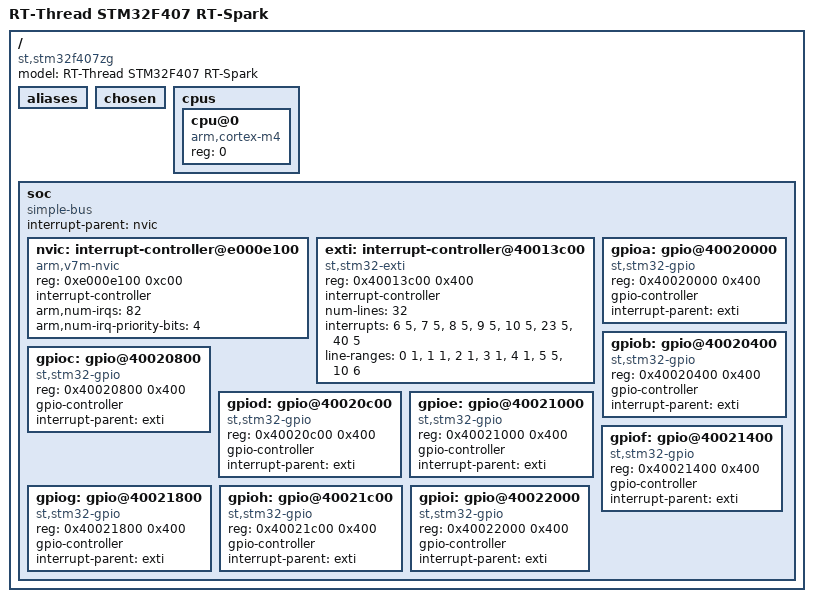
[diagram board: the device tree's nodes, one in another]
/dts-v1/;

#include <dt-bindings/pin/pin.h>

/ {
    compatible = "st,stm32f407zg", "st,stm32f4";
    model = "RT-Thread STM32F407 RT-Spark";
    #address-cells = <1>;
    #size-cells = <1>;

    aliases {
    };

    chosen {
    };

    cpus {
        #address-cells = <1>;
        #size-cells = <0>;

        cpu@0 {
            compatible = "arm,cortex-m4";
            device_type = "cpu";
            reg = <0>;
        };
    };

    soc {
        compatible = "simple-bus";
        #address-cells = <1>;
        #size-cells = <1>;
        ranges;
        interrupt-parent = <&nvic>;

        nvic: interrupt-controller@e000e100 {
            compatible = "arm,v7m-nvic";
            reg = <0xe000e100 0xc00>;
            interrupt-controller;
            #interrupt-cells = <2>;
            arm,num-irqs = <82>;
            arm,num-irq-priority-bits = <4>;
        };

        exti: interrupt-controller@40013c00 {
            compatible = "st,stm32-exti";
            reg = <0x40013c00 0x400>;
            interrupt-controller;
            #interrupt-cells = <1>;
            #address-cells = <0>;
            num-lines = <32>;
            interrupts = <6 5>, <7 5>, <8 5>, <9 5>,
                         <10 5>, <23 5>, <40 5>;
            interrupt-names = "line0", "line1", "line2", "line3",
                              "line4", "line5-9", "line10-15";
            line-ranges = <0 1>, <1 1>, <2 1>, <3 1>,
                          <4 1>, <5 5>, <10 6>;
        };

        gpioa: gpio@40020000 {
            compatible = "st,stm32-gpio";
            reg = <0x40020000 0x400>;
            gpio-controller;
            #gpio-cells = <2>;
            interrupt-parent = <&exti>;
        };

        gpiob: gpio@40020400 {
            compatible = "st,stm32-gpio";
            reg = <0x40020400 0x400>;
            gpio-controller;
            #gpio-cells = <2>;
            interrupt-parent = <&exti>;
        };

        gpioc: gpio@40020800 {
            compatible = "st,stm32-gpio";
            reg = <0x40020800 0x400>;
            gpio-controller;
            #gpio-cells = <2>;
            interrupt-parent = <&exti>;
        };

        gpiod: gpio@40020c00 {
            compatible = "st,stm32-gpio";
            reg = <0x40020c00 0x400>;
            gpio-controller;
            #gpio-cells = <2>;
            interrupt-parent = <&exti>;
        };

        gpioe: gpio@40021000 {
            compatible = "st,stm32-gpio";
            reg = <0x40021000 0x400>;
            gpio-controller;
            #gpio-cells = <2>;
            interrupt-parent = <&exti>;
        };

        gpiof: gpio@40021400 {
            compatible = "st,stm32-gpio";
            reg = <0x40021400 0x400>;
            gpio-controller;
            #gpio-cells = <2>;
            interrupt-parent = <&exti>;
        };

        gpiog: gpio@40021800 {
            compatible = "st,stm32-gpio";
            reg = <0x40021800 0x400>;
            gpio-controller;
            #gpio-cells = <2>;
            interrupt-parent = <&exti>;
        };

        gpioh: gpio@40021c00 {
            compatible = "st,stm32-gpio";
            reg = <0x40021c00 0x400>;
            gpio-controller;
            #gpio-cells = <2>;
            interrupt-parent = <&exti>;
        };

        gpioi: gpio@40022000 {
            compatible = "st,stm32-gpio";
            reg = <0x40022000 0x400>;
            gpio-controller;
            #gpio-cells = <2>;
            interrupt-parent = <&exti>;
        };
    };
};
